VERSION ""

NS_ :

BS_:

BU_: XXX DSU HCU EPS IPAS CGW

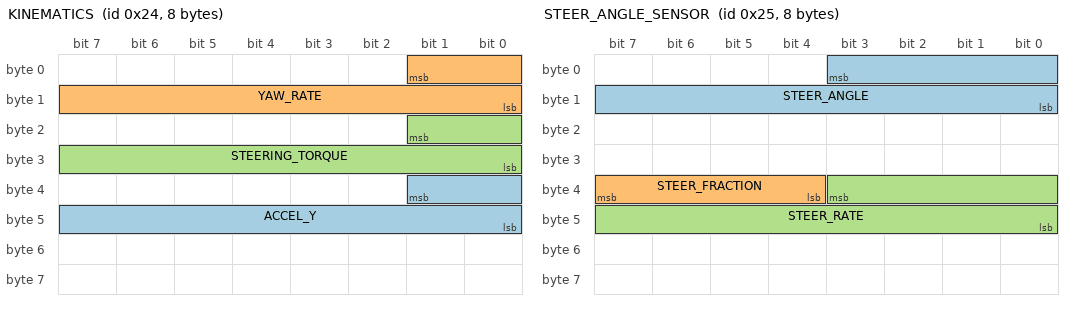
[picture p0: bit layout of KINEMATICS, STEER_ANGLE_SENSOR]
BO_ 36 KINEMATICS: 8 XXX
 SG_ ACCEL_Y : 33|10@0+ (0.03589,-18.375) [0|65535] "m/s^2" XXX
 SG_ YAW_RATE : 1|10@0+ (0.244,-125) [0|65535] "deg/sec" XXX
 SG_ STEERING_TORQUE : 17|10@0+ (1,-512) [0|65535] "" XXX

BO_ 37 STEER_ANGLE_SENSOR: 8 XXX
 SG_ STEER_ANGLE : 3|12@0- (1.5,0) [-500|500] "deg" XXX
 SG_ STEER_FRACTION : 39|4@0- (0.1,0) [-0.7|0.7] "deg" XXX
 SG_ STEER_RATE : 35|12@0- (1,0) [-2000|2000] "deg/s" XXX

BO_ 166 BRAKE: 8 XXX
 SG_ BRAKE_AMOUNT : 7|8@0+ (1,0) [0|255] "" XXX
 SG_ BRAKE_PEDAL : 23|8@0+ (1,0) [0|255] "" XXX

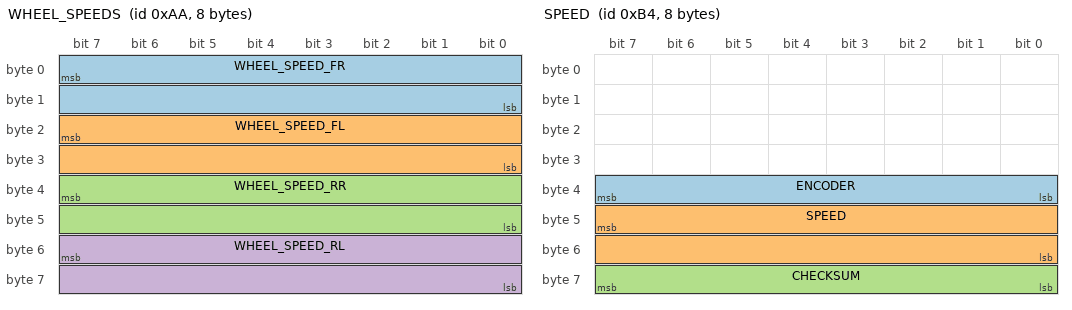
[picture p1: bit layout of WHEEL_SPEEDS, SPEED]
BO_ 170 WHEEL_SPEEDS: 8 XXX
 SG_ WHEEL_SPEED_FR : 7|16@0+ (0.01,-67.67) [0|250] "kph" XXX
 SG_ WHEEL_SPEED_FL : 23|16@0+ (0.01,-67.67) [0|250] "kph" XXX
 SG_ WHEEL_SPEED_RR : 39|16@0+ (0.01,-67.67) [0|250] "kph" XXX
 SG_ WHEEL_SPEED_RL : 55|16@0+ (0.01,-67.67) [0|250] "kph" XXX

BO_ 180 SPEED: 8 XXX
 SG_ ENCODER : 39|8@0+ (1,0) [0|255] "" XXX
 SG_ SPEED : 47|16@0+ (0.01,0) [0|250] "kph" XXX
 SG_ CHECKSUM : 63|8@0+ (1,0) [0|255] "" XXX

BO_ 353 DSU_SPEED: 8 XXX
 SG_ FORWARD_SPEED : 15|16@0- (0.00390625,-30) [0|255] "kph" XXX

BO_ 452 ENGINE_RPM: 8 CGW
 SG_ RPM : 7|16@0- (0.78125,0) [0|0] "rpm" SCS

BO_ 552 ACCELEROMETER: 4 XXX
 SG_ ACCEL_Z : 22|15@0- (1,0) [0|32767] "" XXX
 SG_ ACCEL_X : 6|15@0- (0.001,0) [-20|20] "m/s2" XXX

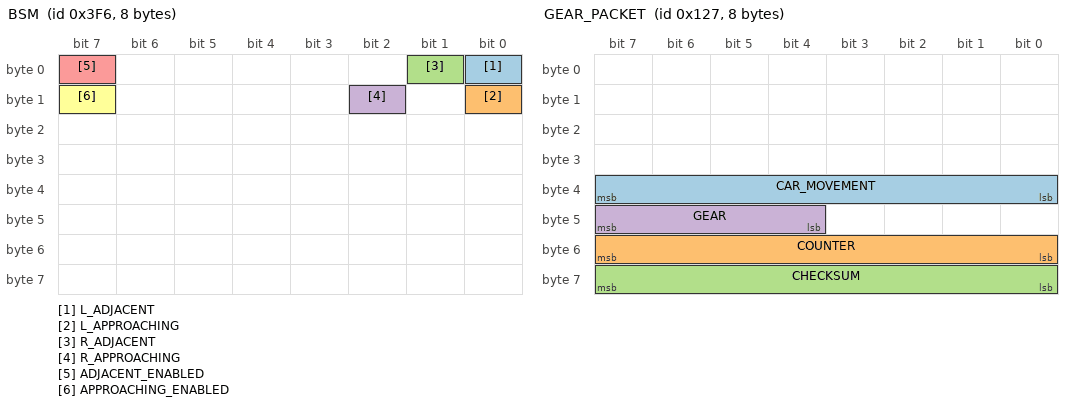
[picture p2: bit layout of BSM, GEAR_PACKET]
BO_ 1014 BSM: 8 XXX
 SG_ L_ADJACENT : 0|1@0+ (1,0) [0|1] "" XXX
 SG_ L_APPROACHING : 8|1@0+ (1,0) [0|1] "" XXX
 SG_ R_ADJACENT : 1|1@0+ (1,0) [0|1] "" XXX
 SG_ R_APPROACHING : 10|1@0+ (1,0) [0|1] "" XXX
 SG_ ADJACENT_ENABLED : 7|1@0+ (1,0) [0|1] "" XXX
 SG_ APPROACHING_ENABLED : 15|1@0+ (1,0) [0|1] "" XXX

BO_ 295 GEAR_PACKET: 8 XXX
 SG_ CAR_MOVEMENT : 39|8@0- (1,0) [0|255] "" XXX
 SG_ COUNTER : 55|8@0+ (1,0) [0|255] "" XXX
 SG_ CHECKSUM : 63|8@0+ (1,0) [0|255] "" XXX
 SG_ GEAR : 47|4@0+ (1,0) [0|15] "" XXX

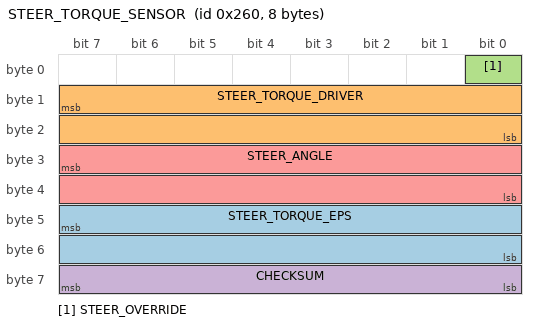
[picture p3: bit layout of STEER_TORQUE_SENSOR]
BO_ 608 STEER_TORQUE_SENSOR: 8 XXX
 SG_ STEER_TORQUE_EPS : 47|16@0- (0.5475,0) [-20000|20000] "" XXX
 SG_ STEER_TORQUE_DRIVER : 15|16@0- (1,0) [-32768|32767] "" XXX
 SG_ STEER_OVERRIDE : 0|1@0+ (1,0) [0|1] "" XXX
 SG_ CHECKSUM : 63|8@0+ (1,0) [0|255] "" XXX
 SG_ STEER_ANGLE : 31|16@0- (0.0573,0) [-500|500] "" XXX
